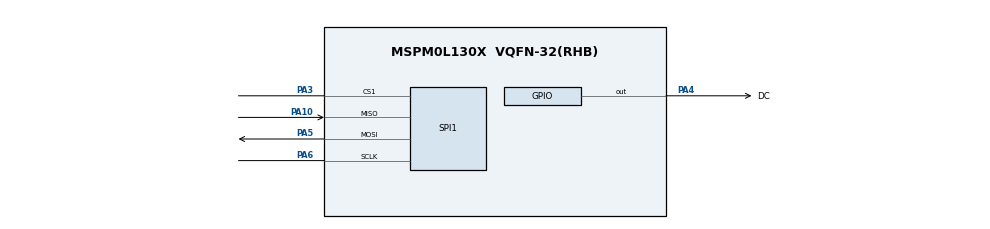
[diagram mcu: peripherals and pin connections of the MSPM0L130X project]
/**
 * @cliArgs --device "MSPM0L130X" --package "VQFN-32(RHB)" --part "Default" --product "mspm0_sdk@1.20.01.06"
 * @versions {"tool":"1.18.1+3343"}
 */

/**
 * Import the modules used in this configuration.
 */
const Board  = scripting.addModule("/ti/driverlib/Board");
const GPIO   = scripting.addModule("/ti/driverlib/GPIO", {}, false);
const GPIO1  = GPIO.addInstance();
const SPI    = scripting.addModule("/ti/driverlib/SPI", {}, false);
const SPI1   = SPI.addInstance();
const SYSCTL = scripting.addModule("/ti/driverlib/SYSCTL");

/**
 * Write custom configuration values to the imported modules.
 */
const gate6  = system.clockTree["MFCLKGATE"];
gate6.enable = true;

const gate7  = system.clockTree["MFPCLKGATE"];
gate7.enable = true;


GPIO1.$name                         = "OLED";
GPIO1.associatedPins[0].$name       = "DC";
GPIO1.associatedPins[0].pin.$assign = "PA4";

SPI1.$name                      = "SPI_0";
SPI1.chipSelect                 = ["0","1"];
SPI1.peripheral.sclkPin.$assign = "PA6";
SPI1.peripheral.mosiPin.$assign = "PA5";
SPI1.peripheral.misoPin.$assign = "PA10";
SPI1.peripheral.cs1Pin.$assign  = "PA3";
SPI1.sclkPinConfig.$name        = "ti_driverlib_gpio_GPIOPinGeneric0";
SPI1.mosiPinConfig.$name        = "ti_driverlib_gpio_GPIOPinGeneric1";
SPI1.misoPinConfig.$name        = "ti_driverlib_gpio_GPIOPinGeneric2";
SPI1.cs0PinConfig.$name         = "ti_driverlib_gpio_GPIOPinGeneric4";
SPI1.cs1PinConfig.$name         = "ti_driverlib_gpio_GPIOPinGeneric3";

SYSCTL.MFCLKEn     = true;
SYSCTL.MFPCLKEn    = true;
SYSCTL.clockTreeEn = true;

/**
 * Pinmux solution for unlocked pins/peripherals. This ensures that minor changes to the automatic solver in a future
 * version of the tool will not impact the pinmux you originally saw.  These lines can be completely deleted in order to
 * re-solve from scratch.
 */
Board.peripheral.$suggestSolution          = "DEBUGSS";
Board.peripheral.swclkPin.$suggestSolution = "PA20";
Board.peripheral.swdioPin.$suggestSolution = "PA19";
SPI1.peripheral.$suggestSolution           = "SPI0";
SPI1.peripheral.cs0Pin.$suggestSolution    = "PA2";
